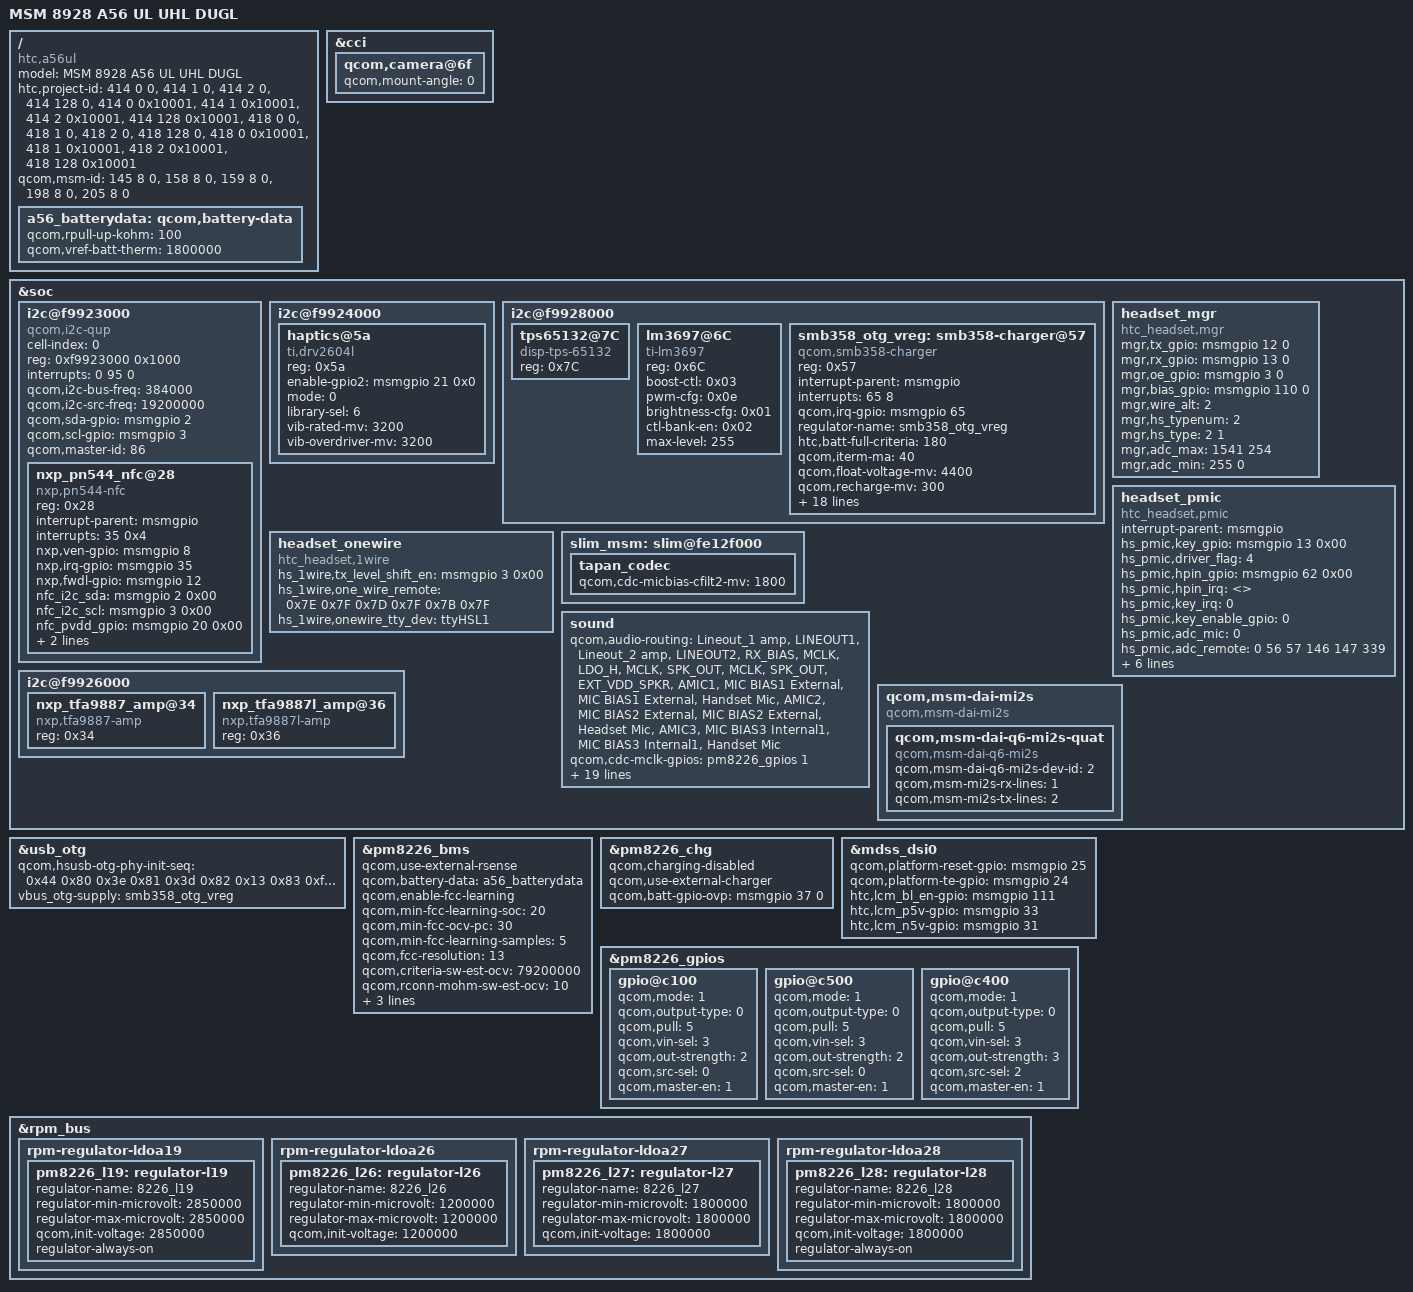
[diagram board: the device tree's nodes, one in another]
/* Copyright (c) 2013, The Linux Foundation. All rights reserved.
 *
 * This program is free software; you can redistribute it and/or modify
 * it under the terms of the GNU General Public License version 2 and
 * only version 2 as published by the Free Software Foundation.
 *
 * This program is distributed in the hope that it will be useful,
 * but WITHOUT ANY WARRANTY; without even the implied warranty of
 * MERCHANTABILITY or FITNESS FOR A PARTICULAR PURPOSE.  See the
 * GNU General Public License for more details.
 */

/dts-v1/;
/include/ "msm8926.dtsi"
/include/ "msm8226-720p-mtp.dtsi"
/include/ "msm8928-camera-sensor-A56.dtsi"
/include/ "dsi-panel-a56.dtsi"
/include/ "msm8226-a56-storage.dtsi"
/include/ "msm8926-touch-a56-config.dtsi"
/include/ "msm8926-flashlight-a56.dtsi"
/include/ "msm8926-key-a56.dtsi"
/include/ "msm8926-a56-hallsensor.dtsi"
/include/ "msm8926-a56-shub.dtsi"

/ {
	model = "MSM 8928 A56 UL UHL DUGL";
	compatible = "htc,a56ul", "qcom,msm8926-mtp", "qcom,msm8926", "qcom,mtp";
	htc,project-id = <414 0 0>, <414 1 0>, <414 2 0>, <414 128 0>, <414 0 0x10001>, <414 1 0x10001>, <414 2 0x10001>, <414 128 0x10001>, <418 0 0>, <418 1 0>, <418 2 0>, <418 128 0>, <418 0 0x10001>, <418 1 0x10001>, <418 2 0x10001>, <418 128 0x10001>;  /* <pid hw-version reserve> */
	qcom,msm-id = <145 8 0>,
		      <158 8 0>,
		      <159 8 0>,
		      <198 8 0>,
		      <205 8 0>;
};

&cci {
	/* Rotate rear camera to 0 degrees */
	qcom,camera@6f {
	qcom,mount-angle = <0>;
	};
};

&soc {

	i2c@f9923000 { /* BLSP-1 QUP-1 */
		cell-index = <0>;
		compatible = "qcom,i2c-qup";
		reg = <0xf9923000 0x1000>;
		#address-cells = <1>;
		#size-cells = <0>;
		reg-names = "qup_phys_addr";
		interrupts = <0 95 0>;
		interrupt-names = "qup_err_intr";
		qcom,i2c-bus-freq = <384000>;
		qcom,i2c-src-freq = <19200000>;
		qcom,sda-gpio = <&msmgpio 2 0>;
		qcom,scl-gpio = <&msmgpio 3 0>;
		qcom,master-id = <86>;
		nxp_pn544_nfc@28 {
			compatible = "nxp,pn544-nfc";
			reg = <0x28>;
			interrupt-parent = <&msmgpio>;
			interrupts = <35 0x4>;
			nxp,ven-gpio = <&msmgpio 8 0x00>;
			nxp,irq-gpio = <&msmgpio 35 0x00>;
			nxp,fwdl-gpio = <&msmgpio 12 0x00>;
                        nfc_i2c_sda = <&msmgpio 2 0x00>;
                        nfc_i2c_scl = <&msmgpio 3 0x00>;
			nfc_pvdd_gpio = <&msmgpio 20 0x00>;
			nxp,ven_isinvert = <0>;
			nxp,isalive = <1>;
		};
	};

	i2c@f9924000 {
            haptics@5a {
		compatible = "ti,drv2604l";
		reg = <0x5a>;
		enable-gpio2 = <&msmgpio 21 0x0>;
		mode = <0>; //DRV260X_LRA_MODE
		library-sel = <6>; //DRV260X_LIB_LRA
		vib-rated-mv = <3200>;
		vib-overdriver-mv = <3200>;
		};
	};

	i2c@f9928000 {
		tps65132@7C {
			compatible = "disp-tps-65132";
			reg = <0x7C>;
		};

		lm3697@6C {
			compatible = "ti-lm3697";
			reg = <0x6C>;
			boost-ctl = <0x03>; /* 24V, 1MHz */
			pwm-cfg = <0x0e>; /* control B PWM enable */
			brightness-cfg = <0x01>; /* linear mapping */
			ctl-bank-en = <0x02>; /* control B enable */
			max-level = <255>;
		};

		smb358_otg_vreg: smb358-charger@57 {
			compatible = "qcom,smb358-charger";
			reg = <0x57>;
			interrupt-parent = <&msmgpio>;
			interrupts = <65 8>;
			qcom,irq-gpio = <&msmgpio 65 0x00>;
			regulator-name = "smb358_otg_vreg";
			/* pinctrl-names = "default", "batt_ovp_1_init"; */
			/* pinctrl-0 = <&smb_int_default>; */
			/* pinctrl-1 = <&batt_ovp_1_default>; */
			/* qcom,vcc-i2c-supply = <&pm8909_lvs1>; */
			htc,batt-full-criteria = <180>;
			qcom,iterm-ma = <40>;
			qcom,float-voltage-mv = <4400>;
			qcom,recharge-mv = <300>;
			qcom,disable-apsd;
			qcom,chg-inhibit-disabled;
			qcom,using-pmic-therm;
			htc,is-embeded-batt;
			/* qcom,bms-controlled-charging; */
			qcom,fastchg-current-max-ma = <2000>;
			qcom,bms-psy-name = "bms";
			qcom,chg-vadc = <&pm8226_vadc>;
			qcom,chg-adc_tm = <&pm8226_adc_tm>;
			qcom,hot-bat-decidegc = <550>;
			qcom,cold-bat-decidegc = <0>;
			qcom,bat-present-decidegc = <200>;
			qcom,warm-bat-decidegc = <480>;
			qcom,cool-bat-decidegc = <100>;
			qcom,warm-bat-ma = <1800>;
			qcom,cool-bat-ma = <1300>;
			qcom,warm-bat-mv = <4000>;
			qcom,cool-bat-mv = <4000>;
			qcom,charging-timeout = <764>;
		};
	};

	headset_mgr {
		compatible   = "htc_headset,mgr";
		mgr,tx_gpio  = <&msmgpio 12 0>;
		mgr,rx_gpio  = <&msmgpio 13 0>;
		mgr,oe_gpio  = <&msmgpio 3 0>;
		mgr,bias_gpio  = <&msmgpio 110 0>;
		mgr,wire_alt = <2>;
		mgr,hs_typenum   = <2>;
		mgr,hs_type      = <2 1>;
		mgr,adc_max      = <1541 254>; // <1557 254>, 1% tolerance
		mgr,adc_min      = <255 0>;
	};

	headset_pmic {
		compatible = "htc_headset,pmic";
		interrupt-parent = <&msmgpio>;
		hs_pmic,key_gpio 	= <&msmgpio 13 0x00>;
		hs_pmic,driver_flag     = <4>;
		hs_pmic,hpin_gpio       = <&msmgpio 62 0x00>;
		hs_pmic,hpin_irq        = <>;
		hs_pmic,key_irq         = <0>;
		hs_pmic,key_enable_gpio = <0>;
		hs_pmic,adc_mic         = <0>;
		hs_pmic,adc_remote      = <0 56 57 146 147 339>;
		hs_pmic,adc_channel	= <17>;		//P_MUX2_1_1
		hs_pmic,adc_mpp         = <0>;
		hs_pmic,adc_amux        = <0>;
		hs_pmic,hs_controller   = <0>;
		hs_pmic,hs_switch       = <0>;
		qcom,headset-vadc	= <&pm8226_vadc>;
	};

	headset_onewire {
		compatible = "htc_headset,1wire";
		hs_1wire,tx_level_shift_en = <&msmgpio 3 0x00>;
		hs_1wire,one_wire_remote = <0x7E 0x7F 0x7D 0x7F 0x7B 0x7F>;
		hs_1wire,onewire_tty_dev = "ttyHSL1";
	};

/*Audio config start*/
	slim_msm: slim@fe12f000 {
		tapan_codec {
			qcom,cdc-micbias-cfilt2-mv = <1800>;
		};
	};

	sound {
		qcom,audio-routing =
			"Lineout_1 amp", "LINEOUT1",
			"Lineout_2 amp", "LINEOUT2",
			"RX_BIAS", "MCLK",
			"LDO_H", "MCLK",
			"SPK_OUT", "MCLK",
			"SPK_OUT", "EXT_VDD_SPKR",
			"AMIC1", "MIC BIAS1 External",
			"MIC BIAS1 External", "Handset Mic",
			"AMIC2", "MIC BIAS2 External",
			"MIC BIAS2 External", "Headset Mic",
			"AMIC3", "MIC BIAS3 Internal1",
			"MIC BIAS3 Internal1", "Handset Mic";

		qcom,cdc-mclk-gpios = <&pm8226_gpios 1 0>;
		qcom,cdc-vdd-spkr-gpios = <>;

		qcom,prim-auxpcm-gpio-clk  = <>;
		qcom,prim-auxpcm-gpio-sync = <>;
		qcom,prim-auxpcm-gpio-din  = <>;
		qcom,prim-auxpcm-gpio-dout = <>;
		qcom,sec-auxpcm-gpio-clk  = <>;
		qcom,sec-auxpcm-gpio-sync = <>;
		qcom,sec-auxpcm-gpio-din  = <>;
		qcom,sec-auxpcm-gpio-dout = <>;

		mi2s-gpio-sck   = <&msmgpio 49 0>;
		mi2s-gpio-ws    = <&msmgpio 50 0>;
		mi2s-gpio-sda0  = <&msmgpio 51 0>;
		mi2s-gpio-sda1  = <&msmgpio 52 0>;
		mi2s-afe-portid = <0x1004>;

		rcv-gpio-sel    = <&msmgpio 77 0>;
		rcv-gpio-en     = <&msmgpio 69 0>;

		htc,aud-hw-component = "TFA9887", "TFA9887L";
		htc,aud-digital-mic-en = <0>;
		htc,aud-24b-en = <1>;
	};

        i2c@f9926000 {
                nxp_tfa9887_amp@34 {
                        compatible = "nxp,tfa9887-amp";
                        reg = <0x34>;
                };
                nxp_tfa9887l_amp@36 {
                        compatible = "nxp,tfa9887l-amp";
                        reg = <0x36>;
                };
        };

	qcom,msm-dai-mi2s {
		compatible = "qcom,msm-dai-mi2s";
		qcom,msm-dai-q6-mi2s-quat {
			compatible = "qcom,msm-dai-q6-mi2s";
			qcom,msm-dai-q6-mi2s-dev-id = <2>;
			qcom,msm-mi2s-rx-lines = <1>;
			qcom,msm-mi2s-tx-lines = <2>;
		};
	};
/*Audio config end*/

};

&usb_otg {
    qcom,hsusb-otg-phy-init-seq =
            <0x44 0x80 0x3e 0x81 0x3d 0x82 0x13 0x83 0xffffffff>;
    vbus_otg-supply = <&smb358_otg_vreg>;
};

&pm8226_bms {
	qcom,use-external-rsense;
	qcom,battery-data = <&a56_batterydata>;
	qcom,enable-fcc-learning;
	qcom,min-fcc-learning-soc = <20>;
	qcom,min-fcc-ocv-pc = <30>;
	qcom,min-fcc-learning-samples = <5>;
	qcom,fcc-resolution = <13>;
	qcom,criteria-sw-est-ocv = <79200000>;
	qcom,rconn-mohm-sw-est-ocv = <10>;
	qcom,enable-sw-ocv-in-eoc = <1>;
	qcom,enable-batt-full-fake-ocv = <1>;
	qcom,soc-overrate-criteria-for-sw-ocv = <5>;
	status = "ok";
};

&pm8226_chg {
	status = "ok";
	qcom,charging-disabled;
	qcom,use-external-charger;
	qcom,batt-gpio-ovp = <&msmgpio 37 0>;
};

/ {
	a56_batterydata: qcom,battery-data {
		qcom,rpull-up-kohm = <100>;
		qcom,vref-batt-therm = <1800000>;

			/include/ "batterydata-a56-id1.dtsi"
			/include/ "batterydata-a56-id2.dtsi"
			/include/ "batterydata-a56-unknown-id.dtsi"
	};
};

&mdss_dsi0 {
	qcom,platform-reset-gpio = <&msmgpio 25 0>;
	qcom,platform-te-gpio = <&msmgpio 24 0>;
	htc,lcm_bl_en-gpio = <&msmgpio 111 0>;
	htc,lcm_p5v-gpio = <&msmgpio 33 0>;
	htc,lcm_n5v-gpio = <&msmgpio 31 0>;
};

&pm8226_gpios {

	gpio@c100 { /* GPIO 2 */
		qcom,mode = <1>;
		qcom,output-type = <0>;
		qcom,pull = <5>;
		qcom,vin-sel = <3>;
		qcom,out-strength = <2>;
		qcom,src-sel = <0>;
		qcom,master-en = <1>;
	};

	gpio@c500 { /* GPIO 6 */
		qcom,mode = <1>;
		qcom,output-type = <0>;
		qcom,pull = <5>;
		qcom,vin-sel = <3>;
		qcom,out-strength = <2>;
		qcom,src-sel = <0>;
		qcom,master-en = <1>;
	};

        gpio@c400 { /* GPIO 5 */
                qcom,mode = <1>;
                qcom,output-type = <0>;
                qcom,pull = <5>;
                qcom,vin-sel = <3>;
                qcom,out-strength = <3>;
                qcom,src-sel = <2>;
                qcom,master-en = <1>;
        };
};

&rpm_bus {
	rpm-regulator-ldoa19 {
		status = "okay";
		pm8226_l19: regulator-l19 {
			regulator-name = "8226_l19";
			regulator-min-microvolt = <2850000>;
			regulator-max-microvolt = <2850000>;
			qcom,init-voltage = <2850000>;
			status = "okay";
			regulator-always-on;
		};
	};

        rpm-regulator-ldoa26 {
                status = "okay";
                pm8226_l26: regulator-l26 {
                        regulator-name = "8226_l26";
                        regulator-min-microvolt = <1200000>;
                        regulator-max-microvolt = <1200000>;
                        qcom,init-voltage = <1200000>;
                        status = "okay";
                };
        };

        rpm-regulator-ldoa27 {
                status = "okay";
                pm8226_l27: regulator-l27 {
                        regulator-name = "8226_l27";
                        regulator-min-microvolt = <1800000>;
                        regulator-max-microvolt = <1800000>;
                        qcom,init-voltage = <1800000>;
                        status = "okay";
                };
        };

	rpm-regulator-ldoa28 {
		status = "okay";
		pm8226_l28: regulator-l28 {
			regulator-name = "8226_l28";
			regulator-min-microvolt = <1800000>;
			regulator-max-microvolt = <1800000>;
			qcom,init-voltage = <1800000>;
			status = "okay";
			regulator-always-on;
		};
	};
};
